# ESP32C3 register map
File version: 1.0
CPU: RISC-V RV32IMC single-core 1, little endian, no MPU, FPU, 3 interrupt priority bits
Registers are 32-bit, read-write, reset 0x0 unless marked. A register's access mark holds for its fields unless they carry their own. Offsets are from the block's base; [hi:lo] are bit positions; {n}, {i} and the like mark numbered series.

## SENSITIVE
Base 0x600C1000
0x00 SENSITIVE_ROM_TABLE_LOCK
  [0] SENSITIVE_ROM_TABLE_LOCK
0x04 SENSITIVE_ROM_TABLE
0x08 SENSITIVE_PRIVILEGE_MODE_SEL_LOCK
  [0] SENSITIVE_PRIVILEGE_MODE_SEL_LOCK
0x0C SENSITIVE_PRIVILEGE_MODE_SEL
  [0] SENSITIVE_PRIVILEGE_MODE_SEL
0x10 SENSITIVE_APB_PERIPHERAL_ACCESS_0
  [0] SENSITIVE_APB_PERIPHERAL_ACCESS_LOCK
0x14 SENSITIVE_APB_PERIPHERAL_ACCESS_1
  [0] SENSITIVE_APB_PERIPHERAL_ACCESS_SPLIT_BURST
0x18 SENSITIVE_INTERNAL_SRAM_USAGE_0
  [0] SENSITIVE_INTERNAL_SRAM_USAGE_LOCK
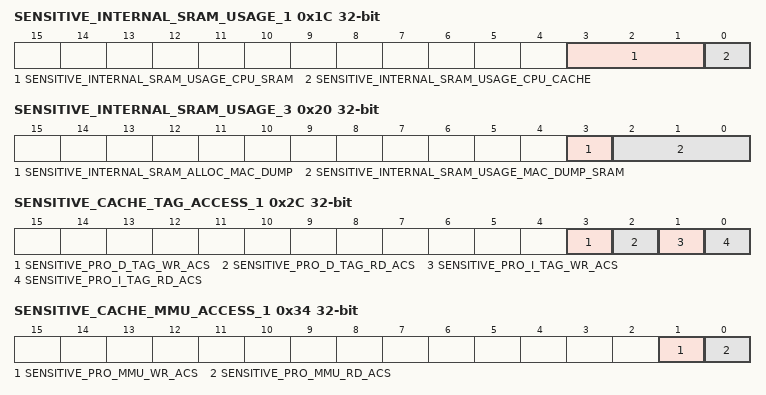
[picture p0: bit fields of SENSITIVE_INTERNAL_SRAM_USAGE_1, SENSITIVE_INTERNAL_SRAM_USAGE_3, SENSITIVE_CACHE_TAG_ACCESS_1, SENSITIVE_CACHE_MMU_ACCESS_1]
0x1C SENSITIVE_INTERNAL_SRAM_USAGE_1
  [3:1] SENSITIVE_INTERNAL_SRAM_USAGE_CPU_SRAM, [0] SENSITIVE_INTERNAL_SRAM_USAGE_CPU_CACHE
0x20 SENSITIVE_INTERNAL_SRAM_USAGE_3
  [3] SENSITIVE_INTERNAL_SRAM_ALLOC_MAC_DUMP, [2:0] SENSITIVE_INTERNAL_SRAM_USAGE_MAC_DUMP_SRAM
0x24 SENSITIVE_INTERNAL_SRAM_USAGE_4
  [0] SENSITIVE_INTERNAL_SRAM_USAGE_LOG_SRAM
0x28 SENSITIVE_CACHE_TAG_ACCESS_0
  [0] SENSITIVE_CACHE_TAG_ACCESS_LOCK
0x2C SENSITIVE_CACHE_TAG_ACCESS_1
  [3] SENSITIVE_PRO_D_TAG_WR_ACS, [2] SENSITIVE_PRO_D_TAG_RD_ACS, [1] SENSITIVE_PRO_I_TAG_WR_ACS, [0] SENSITIVE_PRO_I_TAG_RD_ACS
0x30 SENSITIVE_CACHE_MMU_ACCESS_0
  [0] SENSITIVE_CACHE_MMU_ACCESS_LOCK
0x34 SENSITIVE_CACHE_MMU_ACCESS_1
  [1] SENSITIVE_PRO_MMU_WR_ACS, [0] SENSITIVE_PRO_MMU_RD_ACS
0x38 SENSITIVE_DMA_APBPERI_SPI2_PMS_CONSTRAIN_0
  [0] SENSITIVE_DMA_APBPERI_SPI2_PMS_CONSTRAIN_LOCK
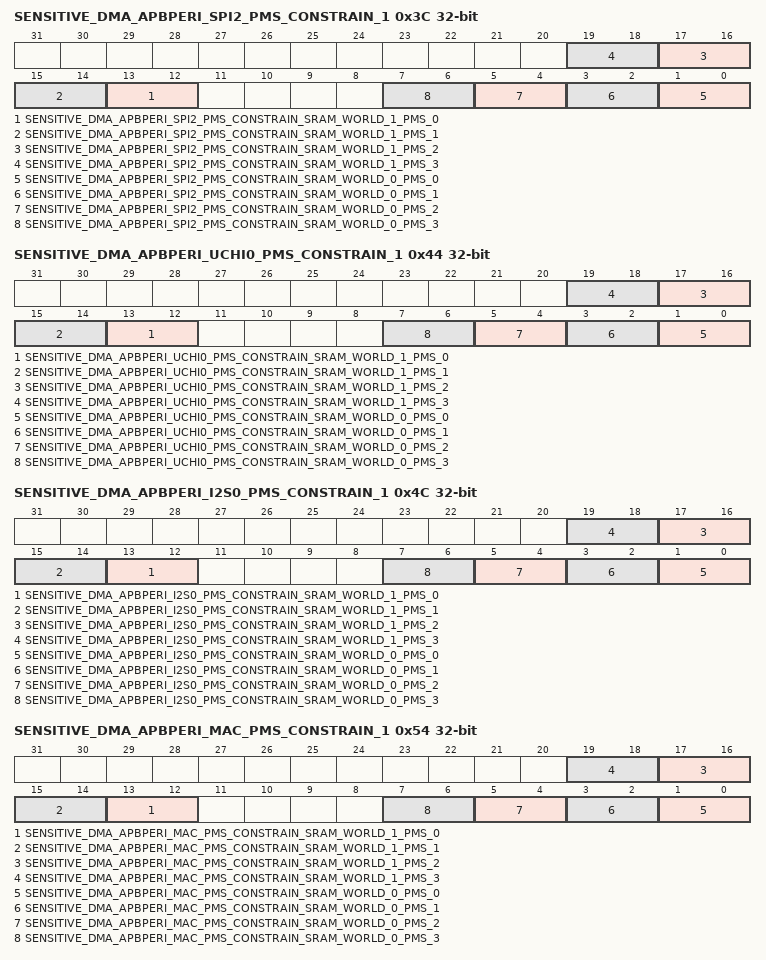
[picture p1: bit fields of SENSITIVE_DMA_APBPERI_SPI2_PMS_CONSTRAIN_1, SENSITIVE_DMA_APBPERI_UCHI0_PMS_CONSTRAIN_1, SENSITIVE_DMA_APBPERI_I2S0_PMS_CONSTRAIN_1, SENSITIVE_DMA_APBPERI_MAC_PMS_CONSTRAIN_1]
0x3C SENSITIVE_DMA_APBPERI_SPI2_PMS_CONSTRAIN_1
  [2n+13:2n+12] SENSITIVE_DMA_APBPERI_SPI2_PMS_CONSTRAIN_SRAM_WORLD_1_PMS_{n} (n=0..3), [2n+1:2n] SENSITIVE_DMA_APBPERI_SPI2_PMS_CONSTRAIN_SRAM_WORLD_0_PMS_{n} (n=0..3)
0x40 SENSITIVE_DMA_APBPERI_UCHI0_PMS_CONSTRAIN_0
  [0] SENSITIVE_DMA_APBPERI_UCHI0_PMS_CONSTRAIN_LOCK
0x44 SENSITIVE_DMA_APBPERI_UCHI0_PMS_CONSTRAIN_1
  [2n+13:2n+12] SENSITIVE_DMA_APBPERI_UCHI0_PMS_CONSTRAIN_SRAM_WORLD_1_PMS_{n} (n=0..3), [2n+1:2n] SENSITIVE_DMA_APBPERI_UCHI0_PMS_CONSTRAIN_SRAM_WORLD_0_PMS_{n} (n=0..3)
0x48 SENSITIVE_DMA_APBPERI_I2S0_PMS_CONSTRAIN_0
  [0] SENSITIVE_DMA_APBPERI_I2S0_PMS_CONSTRAIN_LOCK
0x4C SENSITIVE_DMA_APBPERI_I2S0_PMS_CONSTRAIN_1
  [2n+13:2n+12] SENSITIVE_DMA_APBPERI_I2S0_PMS_CONSTRAIN_SRAM_WORLD_1_PMS_{n} (n=0..3), [2n+1:2n] SENSITIVE_DMA_APBPERI_I2S0_PMS_CONSTRAIN_SRAM_WORLD_0_PMS_{n} (n=0..3)
0x50 SENSITIVE_DMA_APBPERI_MAC_PMS_CONSTRAIN_0
  [0] SENSITIVE_DMA_APBPERI_MAC_PMS_CONSTRAIN_LOCK
0x54 SENSITIVE_DMA_APBPERI_MAC_PMS_CONSTRAIN_1
  [2n+13:2n+12] SENSITIVE_DMA_APBPERI_MAC_PMS_CONSTRAIN_SRAM_WORLD_1_PMS_{n} (n=0..3), [2n+1:2n] SENSITIVE_DMA_APBPERI_MAC_PMS_CONSTRAIN_SRAM_WORLD_0_PMS_{n} (n=0..3)
0x58 SENSITIVE_DMA_APBPERI_BACKUP_PMS_CONSTRAIN_0
  [0] SENSITIVE_DMA_APBPERI_BACKUP_PMS_CONSTRAIN_LOCK
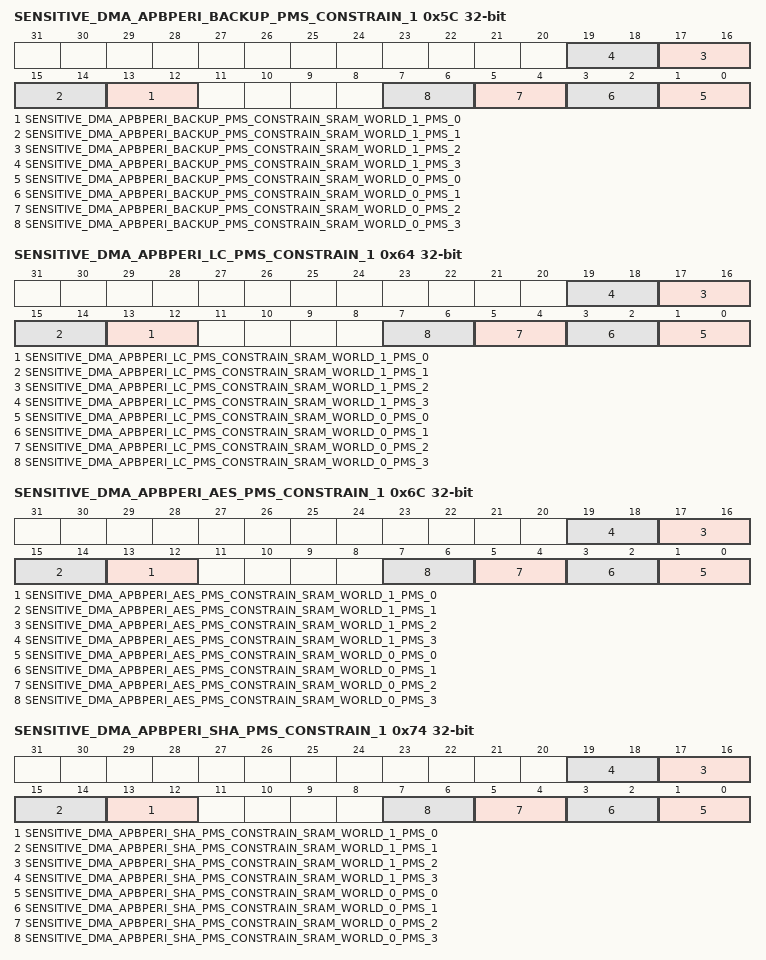
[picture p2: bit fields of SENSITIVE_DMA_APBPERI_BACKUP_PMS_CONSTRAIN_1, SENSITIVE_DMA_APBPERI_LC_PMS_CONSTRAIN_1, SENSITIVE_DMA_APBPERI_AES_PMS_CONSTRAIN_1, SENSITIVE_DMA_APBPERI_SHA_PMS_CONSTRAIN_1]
0x5C SENSITIVE_DMA_APBPERI_BACKUP_PMS_CONSTRAIN_1
  [2n+13:2n+12] SENSITIVE_DMA_APBPERI_BACKUP_PMS_CONSTRAIN_SRAM_WORLD_1_PMS_{n} (n=0..3), [2n+1:2n] SENSITIVE_DMA_APBPERI_BACKUP_PMS_CONSTRAIN_SRAM_WORLD_0_PMS_{n} (n=0..3)
0x60 SENSITIVE_DMA_APBPERI_LC_PMS_CONSTRAIN_0
  [0] SENSITIVE_DMA_APBPERI_LC_PMS_CONSTRAIN_LOCK
0x64 SENSITIVE_DMA_APBPERI_LC_PMS_CONSTRAIN_1
  [2n+13:2n+12] SENSITIVE_DMA_APBPERI_LC_PMS_CONSTRAIN_SRAM_WORLD_1_PMS_{n} (n=0..3), [2n+1:2n] SENSITIVE_DMA_APBPERI_LC_PMS_CONSTRAIN_SRAM_WORLD_0_PMS_{n} (n=0..3)
0x68 SENSITIVE_DMA_APBPERI_AES_PMS_CONSTRAIN_0
  [0] SENSITIVE_DMA_APBPERI_AES_PMS_CONSTRAIN_LOCK
0x6C SENSITIVE_DMA_APBPERI_AES_PMS_CONSTRAIN_1
  [2n+13:2n+12] SENSITIVE_DMA_APBPERI_AES_PMS_CONSTRAIN_SRAM_WORLD_1_PMS_{n} (n=0..3), [2n+1:2n] SENSITIVE_DMA_APBPERI_AES_PMS_CONSTRAIN_SRAM_WORLD_0_PMS_{n} (n=0..3)
0x70 SENSITIVE_DMA_APBPERI_SHA_PMS_CONSTRAIN_0
  [0] SENSITIVE_DMA_APBPERI_SHA_PMS_CONSTRAIN_LOCK
0x74 SENSITIVE_DMA_APBPERI_SHA_PMS_CONSTRAIN_1
  [2n+13:2n+12] SENSITIVE_DMA_APBPERI_SHA_PMS_CONSTRAIN_SRAM_WORLD_1_PMS_{n} (n=0..3), [2n+1:2n] SENSITIVE_DMA_APBPERI_SHA_PMS_CONSTRAIN_SRAM_WORLD_0_PMS_{n} (n=0..3)
0x78 SENSITIVE_DMA_APBPERI_ADC_DAC_PMS_CONSTRAIN_0
  [0] SENSITIVE_DMA_APBPERI_ADC_DAC_PMS_CONSTRAIN_LOCK
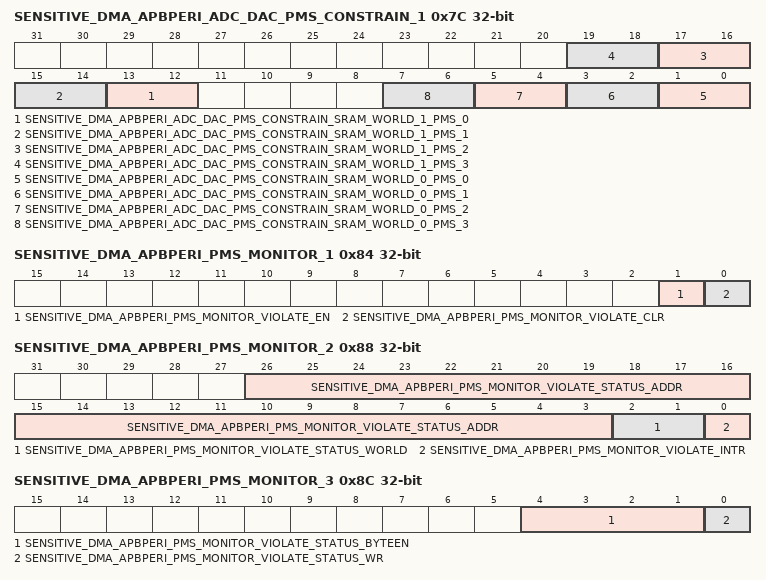
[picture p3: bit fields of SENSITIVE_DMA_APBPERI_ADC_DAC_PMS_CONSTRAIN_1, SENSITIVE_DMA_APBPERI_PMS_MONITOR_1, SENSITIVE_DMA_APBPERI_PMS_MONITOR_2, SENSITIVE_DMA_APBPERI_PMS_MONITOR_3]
0x7C SENSITIVE_DMA_APBPERI_ADC_DAC_PMS_CONSTRAIN_1
  [2n+13:2n+12] SENSITIVE_DMA_APBPERI_ADC_DAC_PMS_CONSTRAIN_SRAM_WORLD_1_PMS_{n} (n=0..3), [2n+1:2n] SENSITIVE_DMA_APBPERI_ADC_DAC_PMS_CONSTRAIN_SRAM_WORLD_0_PMS_{n} (n=0..3)
0x80 SENSITIVE_DMA_APBPERI_PMS_MONITOR_0
  [0] SENSITIVE_DMA_APBPERI_PMS_MONITOR_LOCK
0x84 SENSITIVE_DMA_APBPERI_PMS_MONITOR_1
  [1] SENSITIVE_DMA_APBPERI_PMS_MONITOR_VIOLATE_EN, [0] SENSITIVE_DMA_APBPERI_PMS_MONITOR_VIOLATE_CLR
0x88 SENSITIVE_DMA_APBPERI_PMS_MONITOR_2 ro
  [26:3] SENSITIVE_DMA_APBPERI_PMS_MONITOR_VIOLATE_STATUS_ADDR, [2:1] SENSITIVE_DMA_APBPERI_PMS_MONITOR_VIOLATE_STATUS_WORLD, [0] SENSITIVE_DMA_APBPERI_PMS_MONITOR_VIOLATE_INTR
0x8C SENSITIVE_DMA_APBPERI_PMS_MONITOR_3 ro
  [4:1] SENSITIVE_DMA_APBPERI_PMS_MONITOR_VIOLATE_STATUS_BYTEEN, [0] SENSITIVE_DMA_APBPERI_PMS_MONITOR_VIOLATE_STATUS_WR
0x90 SENSITIVE_CORE_X_IRAM0_DRAM0_DMA_SPLIT_LINE_CONSTRAIN_0
  [0] SENSITIVE_CORE_X_IRAM0_DRAM0_DMA_SPLIT_LINE_CONSTRAIN_LOCK
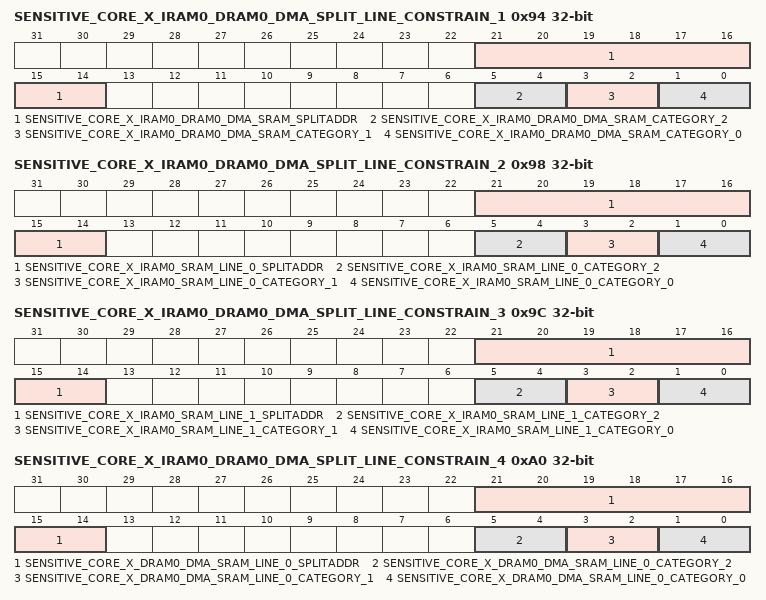
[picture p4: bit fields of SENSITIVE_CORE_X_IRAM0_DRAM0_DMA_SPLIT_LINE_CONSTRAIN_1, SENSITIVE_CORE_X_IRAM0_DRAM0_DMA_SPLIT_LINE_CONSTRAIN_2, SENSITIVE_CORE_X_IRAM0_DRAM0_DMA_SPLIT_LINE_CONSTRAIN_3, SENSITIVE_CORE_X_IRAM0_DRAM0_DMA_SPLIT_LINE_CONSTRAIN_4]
0x94 SENSITIVE_CORE_X_IRAM0_DRAM0_DMA_SPLIT_LINE_CONSTRAIN_1
  [21:14] SENSITIVE_CORE_X_IRAM0_DRAM0_DMA_SRAM_SPLITADDR, [5:4] SENSITIVE_CORE_X_IRAM0_DRAM0_DMA_SRAM_CATEGORY_2, [3:2] SENSITIVE_CORE_X_IRAM0_DRAM0_DMA_SRAM_CATEGORY_1, [1:0] SENSITIVE_CORE_X_IRAM0_DRAM0_DMA_SRAM_CATEGORY_0
0x98 SENSITIVE_CORE_X_IRAM0_DRAM0_DMA_SPLIT_LINE_CONSTRAIN_2
  [21:14] SENSITIVE_CORE_X_IRAM0_SRAM_LINE_0_SPLITADDR, [5:4] SENSITIVE_CORE_X_IRAM0_SRAM_LINE_0_CATEGORY_2, [3:2] SENSITIVE_CORE_X_IRAM0_SRAM_LINE_0_CATEGORY_1, [1:0] SENSITIVE_CORE_X_IRAM0_SRAM_LINE_0_CATEGORY_0
0x9C SENSITIVE_CORE_X_IRAM0_DRAM0_DMA_SPLIT_LINE_CONSTRAIN_3
  [21:14] SENSITIVE_CORE_X_IRAM0_SRAM_LINE_1_SPLITADDR, [5:4] SENSITIVE_CORE_X_IRAM0_SRAM_LINE_1_CATEGORY_2, [3:2] SENSITIVE_CORE_X_IRAM0_SRAM_LINE_1_CATEGORY_1, [1:0] SENSITIVE_CORE_X_IRAM0_SRAM_LINE_1_CATEGORY_0
0xA0 SENSITIVE_CORE_X_IRAM0_DRAM0_DMA_SPLIT_LINE_CONSTRAIN_4
  [21:14] SENSITIVE_CORE_X_DRAM0_DMA_SRAM_LINE_0_SPLITADDR, [5:4] SENSITIVE_CORE_X_DRAM0_DMA_SRAM_LINE_0_CATEGORY_2, [3:2] SENSITIVE_CORE_X_DRAM0_DMA_SRAM_LINE_0_CATEGORY_1, [1:0] SENSITIVE_CORE_X_DRAM0_DMA_SRAM_LINE_0_CATEGORY_0
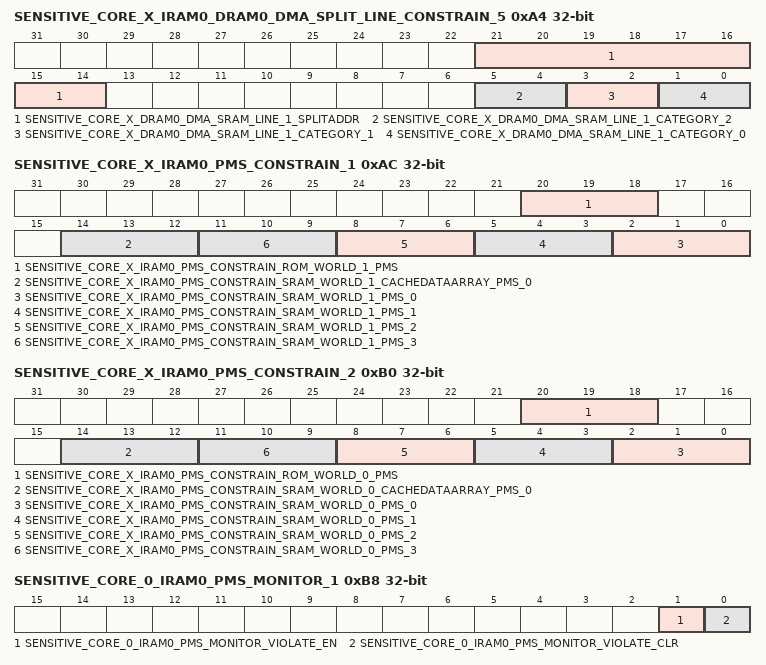
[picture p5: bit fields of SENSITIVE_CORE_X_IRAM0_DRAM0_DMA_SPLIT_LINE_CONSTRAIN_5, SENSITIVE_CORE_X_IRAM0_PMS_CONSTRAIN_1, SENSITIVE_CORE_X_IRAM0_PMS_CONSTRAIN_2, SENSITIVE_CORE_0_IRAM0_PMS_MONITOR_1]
0xA4 SENSITIVE_CORE_X_IRAM0_DRAM0_DMA_SPLIT_LINE_CONSTRAIN_5
  [21:14] SENSITIVE_CORE_X_DRAM0_DMA_SRAM_LINE_1_SPLITADDR, [5:4] SENSITIVE_CORE_X_DRAM0_DMA_SRAM_LINE_1_CATEGORY_2, [3:2] SENSITIVE_CORE_X_DRAM0_DMA_SRAM_LINE_1_CATEGORY_1, [1:0] SENSITIVE_CORE_X_DRAM0_DMA_SRAM_LINE_1_CATEGORY_0
0xA8 SENSITIVE_CORE_X_IRAM0_PMS_CONSTRAIN_0
  [0] SENSITIVE_CORE_X_IRAM0_PMS_CONSTRAIN_LOCK
0xAC SENSITIVE_CORE_X_IRAM0_PMS_CONSTRAIN_1
  [20:18] SENSITIVE_CORE_X_IRAM0_PMS_CONSTRAIN_ROM_WORLD_1_PMS, [14:12] SENSITIVE_CORE_X_IRAM0_PMS_CONSTRAIN_SRAM_WORLD_1_CACHEDATAARRAY_PMS_0, [3n+2:3n] SENSITIVE_CORE_X_IRAM0_PMS_CONSTRAIN_SRAM_WORLD_1_PMS_{n} (n=0..3)
0xB0 SENSITIVE_CORE_X_IRAM0_PMS_CONSTRAIN_2
  [20:18] SENSITIVE_CORE_X_IRAM0_PMS_CONSTRAIN_ROM_WORLD_0_PMS, [14:12] SENSITIVE_CORE_X_IRAM0_PMS_CONSTRAIN_SRAM_WORLD_0_CACHEDATAARRAY_PMS_0, [3n+2:3n] SENSITIVE_CORE_X_IRAM0_PMS_CONSTRAIN_SRAM_WORLD_0_PMS_{n} (n=0..3)
0xB4 SENSITIVE_CORE_0_IRAM0_PMS_MONITOR_0
  [0] SENSITIVE_CORE_0_IRAM0_PMS_MONITOR_LOCK
0xB8 SENSITIVE_CORE_0_IRAM0_PMS_MONITOR_1
  [1] SENSITIVE_CORE_0_IRAM0_PMS_MONITOR_VIOLATE_EN, [0] SENSITIVE_CORE_0_IRAM0_PMS_MONITOR_VIOLATE_CLR
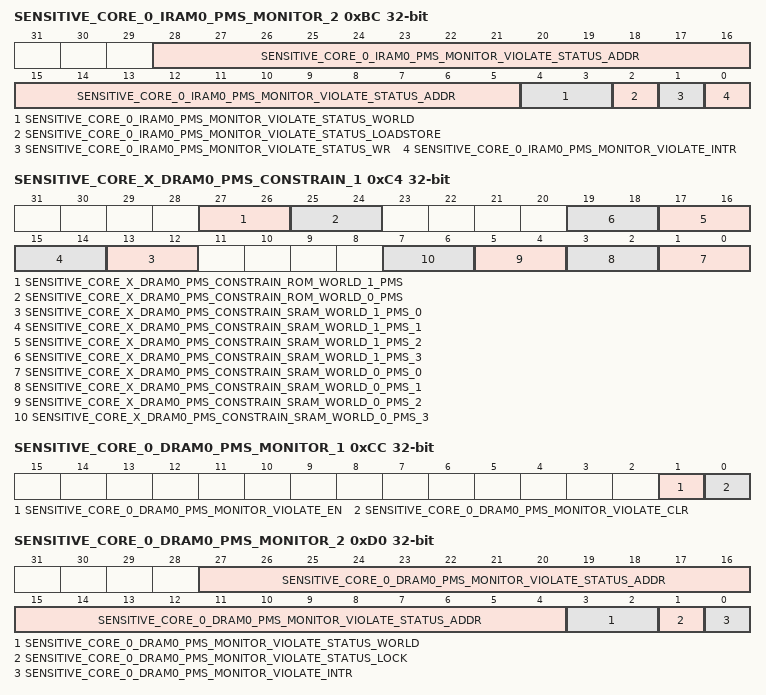
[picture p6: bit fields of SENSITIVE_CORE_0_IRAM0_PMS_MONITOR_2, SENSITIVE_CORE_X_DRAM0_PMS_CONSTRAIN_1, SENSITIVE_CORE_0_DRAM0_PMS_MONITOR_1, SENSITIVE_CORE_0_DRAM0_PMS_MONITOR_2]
0xBC SENSITIVE_CORE_0_IRAM0_PMS_MONITOR_2 ro
  [28:5] SENSITIVE_CORE_0_IRAM0_PMS_MONITOR_VIOLATE_STATUS_ADDR, [4:3] SENSITIVE_CORE_0_IRAM0_PMS_MONITOR_VIOLATE_STATUS_WORLD, [2] SENSITIVE_CORE_0_IRAM0_PMS_MONITOR_VIOLATE_STATUS_LOADSTORE, [1] SENSITIVE_CORE_0_IRAM0_PMS_MONITOR_VIOLATE_STATUS_WR, [0] SENSITIVE_CORE_0_IRAM0_PMS_MONITOR_VIOLATE_INTR
0xC0 SENSITIVE_CORE_X_DRAM0_PMS_CONSTRAIN_0
  [0] SENSITIVE_CORE_X_DRAM0_PMS_CONSTRAIN_LOCK
0xC4 SENSITIVE_CORE_X_DRAM0_PMS_CONSTRAIN_1
  [27:26] SENSITIVE_CORE_X_DRAM0_PMS_CONSTRAIN_ROM_WORLD_1_PMS, [25:24] SENSITIVE_CORE_X_DRAM0_PMS_CONSTRAIN_ROM_WORLD_0_PMS, [2n+13:2n+12] SENSITIVE_CORE_X_DRAM0_PMS_CONSTRAIN_SRAM_WORLD_1_PMS_{n} (n=0..3), [2n+1:2n] SENSITIVE_CORE_X_DRAM0_PMS_CONSTRAIN_SRAM_WORLD_0_PMS_{n} (n=0..3)
0xC8 SENSITIVE_CORE_0_DRAM0_PMS_MONITOR_0
  [0] SENSITIVE_CORE_0_DRAM0_PMS_MONITOR_LOCK
0xCC SENSITIVE_CORE_0_DRAM0_PMS_MONITOR_1
  [1] SENSITIVE_CORE_0_DRAM0_PMS_MONITOR_VIOLATE_EN, [0] SENSITIVE_CORE_0_DRAM0_PMS_MONITOR_VIOLATE_CLR
0xD0 SENSITIVE_CORE_0_DRAM0_PMS_MONITOR_2 ro
  [27:4] SENSITIVE_CORE_0_DRAM0_PMS_MONITOR_VIOLATE_STATUS_ADDR, [3:2] SENSITIVE_CORE_0_DRAM0_PMS_MONITOR_VIOLATE_STATUS_WORLD, [1] SENSITIVE_CORE_0_DRAM0_PMS_MONITOR_VIOLATE_STATUS_LOCK, [0] SENSITIVE_CORE_0_DRAM0_PMS_MONITOR_VIOLATE_INTR
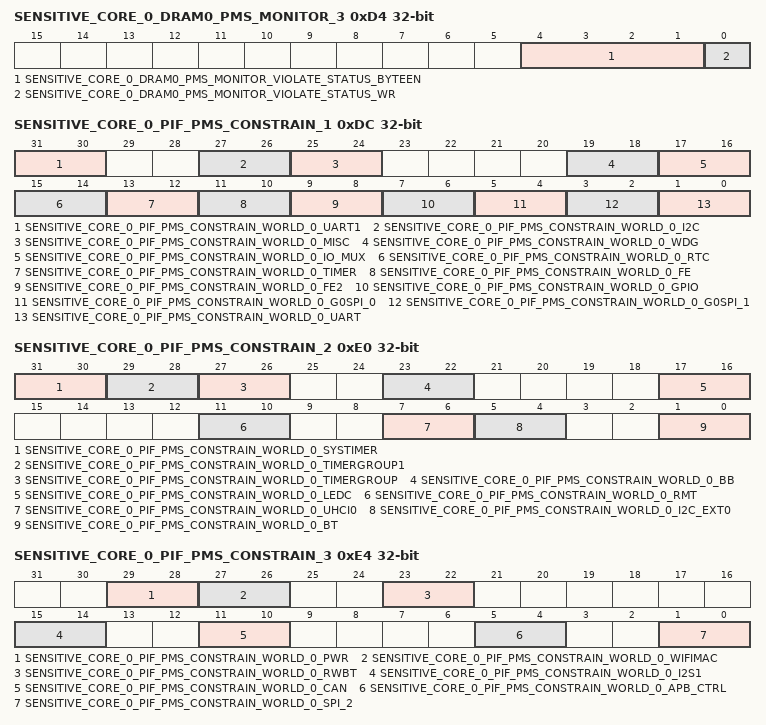
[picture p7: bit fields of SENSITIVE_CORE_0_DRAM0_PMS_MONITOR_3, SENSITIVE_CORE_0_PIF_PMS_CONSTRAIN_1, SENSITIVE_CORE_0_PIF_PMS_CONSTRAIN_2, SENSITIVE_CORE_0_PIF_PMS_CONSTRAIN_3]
0xD4 SENSITIVE_CORE_0_DRAM0_PMS_MONITOR_3 ro
  [4:1] SENSITIVE_CORE_0_DRAM0_PMS_MONITOR_VIOLATE_STATUS_BYTEEN, [0] SENSITIVE_CORE_0_DRAM0_PMS_MONITOR_VIOLATE_STATUS_WR
0xD8 SENSITIVE_CORE_0_PIF_PMS_CONSTRAIN_0
  [0] SENSITIVE_CORE_0_PIF_PMS_CONSTRAIN_LOCK
0xDC SENSITIVE_CORE_0_PIF_PMS_CONSTRAIN_1
  [31:30] SENSITIVE_CORE_0_PIF_PMS_CONSTRAIN_WORLD_0_UART1, [27:26] SENSITIVE_CORE_0_PIF_PMS_CONSTRAIN_WORLD_0_I2C, [25:24] SENSITIVE_CORE_0_PIF_PMS_CONSTRAIN_WORLD_0_MISC, [19:18] SENSITIVE_CORE_0_PIF_PMS_CONSTRAIN_WORLD_0_WDG, [17:16] SENSITIVE_CORE_0_PIF_PMS_CONSTRAIN_WORLD_0_IO_MUX, [15:14] SENSITIVE_CORE_0_PIF_PMS_CONSTRAIN_WORLD_0_RTC, [13:12] SENSITIVE_CORE_0_PIF_PMS_CONSTRAIN_WORLD_0_TIMER, [11:10] SENSITIVE_CORE_0_PIF_PMS_CONSTRAIN_WORLD_0_FE, [9:8] SENSITIVE_CORE_0_PIF_PMS_CONSTRAIN_WORLD_0_FE2, [7:6] SENSITIVE_CORE_0_PIF_PMS_CONSTRAIN_WORLD_0_GPIO, [5:4] SENSITIVE_CORE_0_PIF_PMS_CONSTRAIN_WORLD_0_G0SPI_0, [3:2] SENSITIVE_CORE_0_PIF_PMS_CONSTRAIN_WORLD_0_G0SPI_1, [1:0] SENSITIVE_CORE_0_PIF_PMS_CONSTRAIN_WORLD_0_UART
0xE0 SENSITIVE_CORE_0_PIF_PMS_CONSTRAIN_2
  [31:30] SENSITIVE_CORE_0_PIF_PMS_CONSTRAIN_WORLD_0_SYSTIMER, [29:28] SENSITIVE_CORE_0_PIF_PMS_CONSTRAIN_WORLD_0_TIMERGROUP1, [27:26] SENSITIVE_CORE_0_PIF_PMS_CONSTRAIN_WORLD_0_TIMERGROUP, [23:22] SENSITIVE_CORE_0_PIF_PMS_CONSTRAIN_WORLD_0_BB, [17:16] SENSITIVE_CORE_0_PIF_PMS_CONSTRAIN_WORLD_0_LEDC, [11:10] SENSITIVE_CORE_0_PIF_PMS_CONSTRAIN_WORLD_0_RMT, [7:6] SENSITIVE_CORE_0_PIF_PMS_CONSTRAIN_WORLD_0_UHCI0, [5:4] SENSITIVE_CORE_0_PIF_PMS_CONSTRAIN_WORLD_0_I2C_EXT0, [1:0] SENSITIVE_CORE_0_PIF_PMS_CONSTRAIN_WORLD_0_BT
0xE4 SENSITIVE_CORE_0_PIF_PMS_CONSTRAIN_3
  [29:28] SENSITIVE_CORE_0_PIF_PMS_CONSTRAIN_WORLD_0_PWR, [27:26] SENSITIVE_CORE_0_PIF_PMS_CONSTRAIN_WORLD_0_WIFIMAC, [23:22] SENSITIVE_CORE_0_PIF_PMS_CONSTRAIN_WORLD_0_RWBT, [15:14] SENSITIVE_CORE_0_PIF_PMS_CONSTRAIN_WORLD_0_I2S1, [11:10] SENSITIVE_CORE_0_PIF_PMS_CONSTRAIN_WORLD_0_CAN, [5:4] SENSITIVE_CORE_0_PIF_PMS_CONSTRAIN_WORLD_0_APB_CTRL, [1:0] SENSITIVE_CORE_0_PIF_PMS_CONSTRAIN_WORLD_0_SPI_2
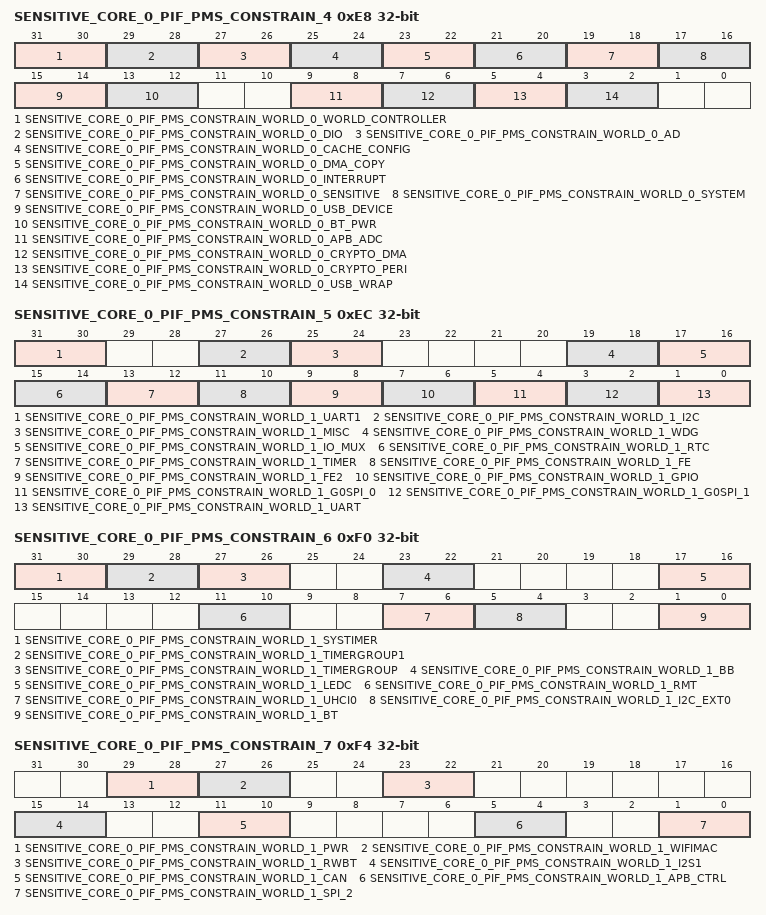
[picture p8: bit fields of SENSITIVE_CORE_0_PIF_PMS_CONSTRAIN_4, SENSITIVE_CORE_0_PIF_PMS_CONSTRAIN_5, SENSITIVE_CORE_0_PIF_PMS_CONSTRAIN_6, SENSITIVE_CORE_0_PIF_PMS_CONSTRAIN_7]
0xE8 SENSITIVE_CORE_0_PIF_PMS_CONSTRAIN_4
  [31:30] SENSITIVE_CORE_0_PIF_PMS_CONSTRAIN_WORLD_0_WORLD_CONTROLLER, [29:28] SENSITIVE_CORE_0_PIF_PMS_CONSTRAIN_WORLD_0_DIO, [27:26] SENSITIVE_CORE_0_PIF_PMS_CONSTRAIN_WORLD_0_AD, [25:24] SENSITIVE_CORE_0_PIF_PMS_CONSTRAIN_WORLD_0_CACHE_CONFIG, [23:22] SENSITIVE_CORE_0_PIF_PMS_CONSTRAIN_WORLD_0_DMA_COPY, [21:20] SENSITIVE_CORE_0_PIF_PMS_CONSTRAIN_WORLD_0_INTERRUPT, [19:18] SENSITIVE_CORE_0_PIF_PMS_CONSTRAIN_WORLD_0_SENSITIVE, [17:16] SENSITIVE_CORE_0_PIF_PMS_CONSTRAIN_WORLD_0_SYSTEM, [15:14] SENSITIVE_CORE_0_PIF_PMS_CONSTRAIN_WORLD_0_USB_DEVICE, [13:12] SENSITIVE_CORE_0_PIF_PMS_CONSTRAIN_WORLD_0_BT_PWR, [9:8] SENSITIVE_CORE_0_PIF_PMS_CONSTRAIN_WORLD_0_APB_ADC, [7:6] SENSITIVE_CORE_0_PIF_PMS_CONSTRAIN_WORLD_0_CRYPTO_DMA, [5:4] SENSITIVE_CORE_0_PIF_PMS_CONSTRAIN_WORLD_0_CRYPTO_PERI, [3:2] SENSITIVE_CORE_0_PIF_PMS_CONSTRAIN_WORLD_0_USB_WRAP
0xEC SENSITIVE_CORE_0_PIF_PMS_CONSTRAIN_5
  [31:30] SENSITIVE_CORE_0_PIF_PMS_CONSTRAIN_WORLD_1_UART1, [27:26] SENSITIVE_CORE_0_PIF_PMS_CONSTRAIN_WORLD_1_I2C, [25:24] SENSITIVE_CORE_0_PIF_PMS_CONSTRAIN_WORLD_1_MISC, [19:18] SENSITIVE_CORE_0_PIF_PMS_CONSTRAIN_WORLD_1_WDG, [17:16] SENSITIVE_CORE_0_PIF_PMS_CONSTRAIN_WORLD_1_IO_MUX, [15:14] SENSITIVE_CORE_0_PIF_PMS_CONSTRAIN_WORLD_1_RTC, [13:12] SENSITIVE_CORE_0_PIF_PMS_CONSTRAIN_WORLD_1_TIMER, [11:10] SENSITIVE_CORE_0_PIF_PMS_CONSTRAIN_WORLD_1_FE, [9:8] SENSITIVE_CORE_0_PIF_PMS_CONSTRAIN_WORLD_1_FE2, [7:6] SENSITIVE_CORE_0_PIF_PMS_CONSTRAIN_WORLD_1_GPIO, [5:4] SENSITIVE_CORE_0_PIF_PMS_CONSTRAIN_WORLD_1_G0SPI_0, [3:2] SENSITIVE_CORE_0_PIF_PMS_CONSTRAIN_WORLD_1_G0SPI_1, [1:0] SENSITIVE_CORE_0_PIF_PMS_CONSTRAIN_WORLD_1_UART
0xF0 SENSITIVE_CORE_0_PIF_PMS_CONSTRAIN_6
  [31:30] SENSITIVE_CORE_0_PIF_PMS_CONSTRAIN_WORLD_1_SYSTIMER, [29:28] SENSITIVE_CORE_0_PIF_PMS_CONSTRAIN_WORLD_1_TIMERGROUP1, [27:26] SENSITIVE_CORE_0_PIF_PMS_CONSTRAIN_WORLD_1_TIMERGROUP, [23:22] SENSITIVE_CORE_0_PIF_PMS_CONSTRAIN_WORLD_1_BB, [17:16] SENSITIVE_CORE_0_PIF_PMS_CONSTRAIN_WORLD_1_LEDC, [11:10] SENSITIVE_CORE_0_PIF_PMS_CONSTRAIN_WORLD_1_RMT, [7:6] SENSITIVE_CORE_0_PIF_PMS_CONSTRAIN_WORLD_1_UHCI0, [5:4] SENSITIVE_CORE_0_PIF_PMS_CONSTRAIN_WORLD_1_I2C_EXT0, [1:0] SENSITIVE_CORE_0_PIF_PMS_CONSTRAIN_WORLD_1_BT
0xF4 SENSITIVE_CORE_0_PIF_PMS_CONSTRAIN_7
  [29:28] SENSITIVE_CORE_0_PIF_PMS_CONSTRAIN_WORLD_1_PWR, [27:26] SENSITIVE_CORE_0_PIF_PMS_CONSTRAIN_WORLD_1_WIFIMAC, [23:22] SENSITIVE_CORE_0_PIF_PMS_CONSTRAIN_WORLD_1_RWBT, [15:14] SENSITIVE_CORE_0_PIF_PMS_CONSTRAIN_WORLD_1_I2S1, [11:10] SENSITIVE_CORE_0_PIF_PMS_CONSTRAIN_WORLD_1_CAN, [5:4] SENSITIVE_CORE_0_PIF_PMS_CONSTRAIN_WORLD_1_APB_CTRL, [1:0] SENSITIVE_CORE_0_PIF_PMS_CONSTRAIN_WORLD_1_SPI_2
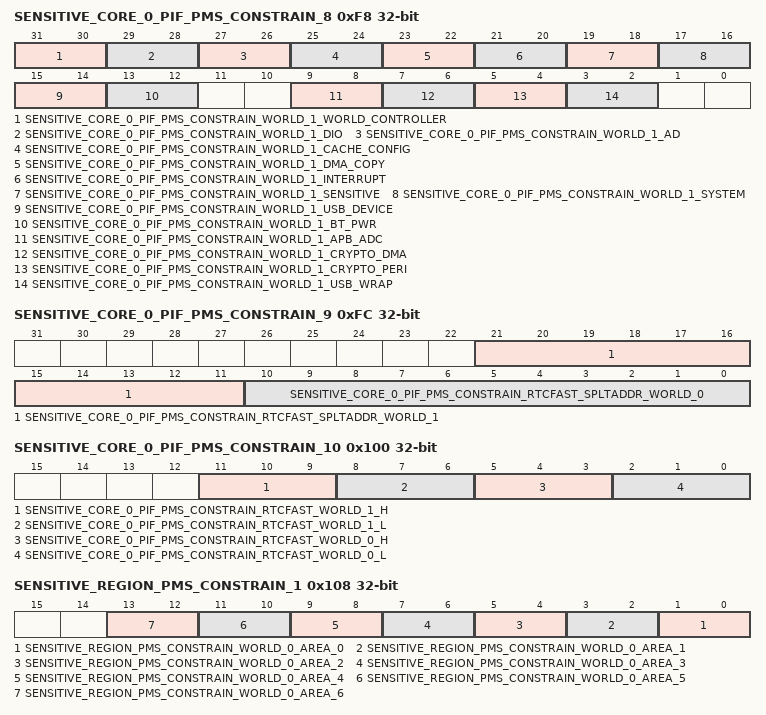
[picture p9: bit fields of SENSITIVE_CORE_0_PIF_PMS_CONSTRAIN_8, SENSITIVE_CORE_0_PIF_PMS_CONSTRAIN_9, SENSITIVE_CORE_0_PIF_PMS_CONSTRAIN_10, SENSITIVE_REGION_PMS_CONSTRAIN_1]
0xF8 SENSITIVE_CORE_0_PIF_PMS_CONSTRAIN_8
  [31:30] SENSITIVE_CORE_0_PIF_PMS_CONSTRAIN_WORLD_1_WORLD_CONTROLLER, [29:28] SENSITIVE_CORE_0_PIF_PMS_CONSTRAIN_WORLD_1_DIO, [27:26] SENSITIVE_CORE_0_PIF_PMS_CONSTRAIN_WORLD_1_AD, [25:24] SENSITIVE_CORE_0_PIF_PMS_CONSTRAIN_WORLD_1_CACHE_CONFIG, [23:22] SENSITIVE_CORE_0_PIF_PMS_CONSTRAIN_WORLD_1_DMA_COPY, [21:20] SENSITIVE_CORE_0_PIF_PMS_CONSTRAIN_WORLD_1_INTERRUPT, [19:18] SENSITIVE_CORE_0_PIF_PMS_CONSTRAIN_WORLD_1_SENSITIVE, [17:16] SENSITIVE_CORE_0_PIF_PMS_CONSTRAIN_WORLD_1_SYSTEM, [15:14] SENSITIVE_CORE_0_PIF_PMS_CONSTRAIN_WORLD_1_USB_DEVICE, [13:12] SENSITIVE_CORE_0_PIF_PMS_CONSTRAIN_WORLD_1_BT_PWR, [9:8] SENSITIVE_CORE_0_PIF_PMS_CONSTRAIN_WORLD_1_APB_ADC, [7:6] SENSITIVE_CORE_0_PIF_PMS_CONSTRAIN_WORLD_1_CRYPTO_DMA, [5:4] SENSITIVE_CORE_0_PIF_PMS_CONSTRAIN_WORLD_1_CRYPTO_PERI, [3:2] SENSITIVE_CORE_0_PIF_PMS_CONSTRAIN_WORLD_1_USB_WRAP
0xFC SENSITIVE_CORE_0_PIF_PMS_CONSTRAIN_9
  [21:11] SENSITIVE_CORE_0_PIF_PMS_CONSTRAIN_RTCFAST_SPLTADDR_WORLD_1, [10:0] SENSITIVE_CORE_0_PIF_PMS_CONSTRAIN_RTCFAST_SPLTADDR_WORLD_0
0x100 SENSITIVE_CORE_0_PIF_PMS_CONSTRAIN_10
  [11:9] SENSITIVE_CORE_0_PIF_PMS_CONSTRAIN_RTCFAST_WORLD_1_H, [8:6] SENSITIVE_CORE_0_PIF_PMS_CONSTRAIN_RTCFAST_WORLD_1_L, [5:3] SENSITIVE_CORE_0_PIF_PMS_CONSTRAIN_RTCFAST_WORLD_0_H, [2:0] SENSITIVE_CORE_0_PIF_PMS_CONSTRAIN_RTCFAST_WORLD_0_L
0x104 SENSITIVE_REGION_PMS_CONSTRAIN_0
  [0] SENSITIVE_REGION_PMS_CONSTRAIN_LOCK
0x108 SENSITIVE_REGION_PMS_CONSTRAIN_1
  [2n+1:2n] SENSITIVE_REGION_PMS_CONSTRAIN_WORLD_0_AREA_{n} (n=0..6)
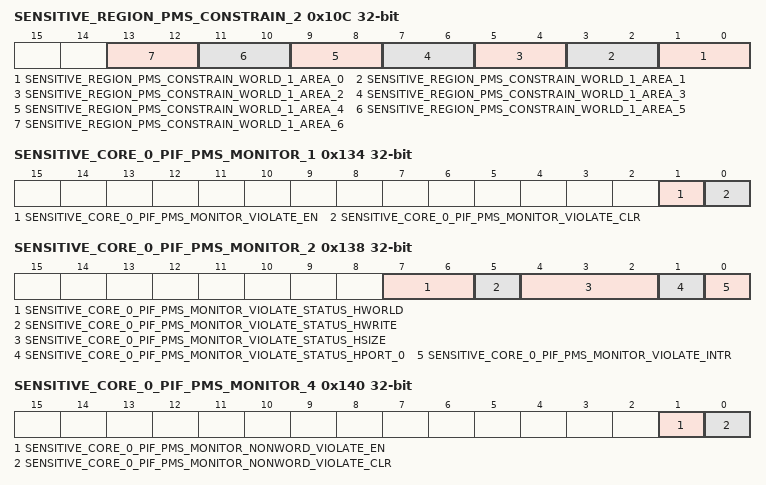
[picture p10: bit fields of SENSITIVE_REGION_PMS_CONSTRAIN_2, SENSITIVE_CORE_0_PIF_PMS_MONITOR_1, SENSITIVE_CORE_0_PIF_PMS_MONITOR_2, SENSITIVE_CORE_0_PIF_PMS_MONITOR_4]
0x10C SENSITIVE_REGION_PMS_CONSTRAIN_2
  [2n+1:2n] SENSITIVE_REGION_PMS_CONSTRAIN_WORLD_1_AREA_{n} (n=0..6)
{0x104+4i} SENSITIVE_REGION_PMS_CONSTRAIN_{i} (i=3..10)
  [29:0] SENSITIVE_REGION_PMS_CONSTRAIN_ADDR_{i-3}
0x130 SENSITIVE_CORE_0_PIF_PMS_MONITOR_0
  [0] SENSITIVE_CORE_0_PIF_PMS_MONITOR_LOCK
0x134 SENSITIVE_CORE_0_PIF_PMS_MONITOR_1
  [1] SENSITIVE_CORE_0_PIF_PMS_MONITOR_VIOLATE_EN, [0] SENSITIVE_CORE_0_PIF_PMS_MONITOR_VIOLATE_CLR
0x138 SENSITIVE_CORE_0_PIF_PMS_MONITOR_2 ro
  [7:6] SENSITIVE_CORE_0_PIF_PMS_MONITOR_VIOLATE_STATUS_HWORLD, [5] SENSITIVE_CORE_0_PIF_PMS_MONITOR_VIOLATE_STATUS_HWRITE, [4:2] SENSITIVE_CORE_0_PIF_PMS_MONITOR_VIOLATE_STATUS_HSIZE, [1] SENSITIVE_CORE_0_PIF_PMS_MONITOR_VIOLATE_STATUS_HPORT_0, [0] SENSITIVE_CORE_0_PIF_PMS_MONITOR_VIOLATE_INTR
0x13C SENSITIVE_CORE_0_PIF_PMS_MONITOR_3 ro
  [31:0] SENSITIVE_CORE_0_PIF_PMS_MONITOR_VIOLATE_STATUS_HADDR
0x140 SENSITIVE_CORE_0_PIF_PMS_MONITOR_4
  [1] SENSITIVE_CORE_0_PIF_PMS_MONITOR_NONWORD_VIOLATE_EN, [0] SENSITIVE_CORE_0_PIF_PMS_MONITOR_NONWORD_VIOLATE_CLR
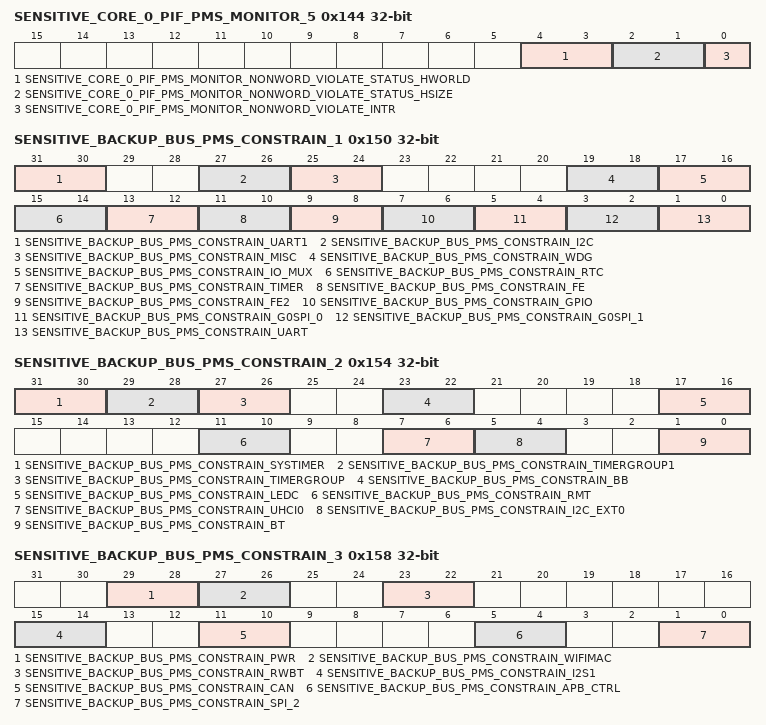
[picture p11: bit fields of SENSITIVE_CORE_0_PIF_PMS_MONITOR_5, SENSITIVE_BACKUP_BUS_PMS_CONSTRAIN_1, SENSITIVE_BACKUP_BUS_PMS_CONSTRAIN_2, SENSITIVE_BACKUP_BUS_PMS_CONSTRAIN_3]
0x144 SENSITIVE_CORE_0_PIF_PMS_MONITOR_5 ro
  [4:3] SENSITIVE_CORE_0_PIF_PMS_MONITOR_NONWORD_VIOLATE_STATUS_HWORLD, [2:1] SENSITIVE_CORE_0_PIF_PMS_MONITOR_NONWORD_VIOLATE_STATUS_HSIZE, [0] SENSITIVE_CORE_0_PIF_PMS_MONITOR_NONWORD_VIOLATE_INTR
0x148 SENSITIVE_CORE_0_PIF_PMS_MONITOR_6 ro
  [31:0] SENSITIVE_CORE_0_PIF_PMS_MONITOR_NONWORD_VIOLATE_STATUS_HADDR
0x14C SENSITIVE_BACKUP_BUS_PMS_CONSTRAIN_0
  [0] SENSITIVE_BACKUP_BUS_PMS_CONSTRAIN_LOCK
0x150 SENSITIVE_BACKUP_BUS_PMS_CONSTRAIN_1
  [31:30] SENSITIVE_BACKUP_BUS_PMS_CONSTRAIN_UART1, [27:26] SENSITIVE_BACKUP_BUS_PMS_CONSTRAIN_I2C, [25:24] SENSITIVE_BACKUP_BUS_PMS_CONSTRAIN_MISC, [19:18] SENSITIVE_BACKUP_BUS_PMS_CONSTRAIN_WDG, [17:16] SENSITIVE_BACKUP_BUS_PMS_CONSTRAIN_IO_MUX, [15:14] SENSITIVE_BACKUP_BUS_PMS_CONSTRAIN_RTC, [13:12] SENSITIVE_BACKUP_BUS_PMS_CONSTRAIN_TIMER, [11:10] SENSITIVE_BACKUP_BUS_PMS_CONSTRAIN_FE, [9:8] SENSITIVE_BACKUP_BUS_PMS_CONSTRAIN_FE2, [7:6] SENSITIVE_BACKUP_BUS_PMS_CONSTRAIN_GPIO, [5:4] SENSITIVE_BACKUP_BUS_PMS_CONSTRAIN_G0SPI_0, [3:2] SENSITIVE_BACKUP_BUS_PMS_CONSTRAIN_G0SPI_1, [1:0] SENSITIVE_BACKUP_BUS_PMS_CONSTRAIN_UART
0x154 SENSITIVE_BACKUP_BUS_PMS_CONSTRAIN_2
  [31:30] SENSITIVE_BACKUP_BUS_PMS_CONSTRAIN_SYSTIMER, [29:28] SENSITIVE_BACKUP_BUS_PMS_CONSTRAIN_TIMERGROUP1, [27:26] SENSITIVE_BACKUP_BUS_PMS_CONSTRAIN_TIMERGROUP, [23:22] SENSITIVE_BACKUP_BUS_PMS_CONSTRAIN_BB, [17:16] SENSITIVE_BACKUP_BUS_PMS_CONSTRAIN_LEDC, [11:10] SENSITIVE_BACKUP_BUS_PMS_CONSTRAIN_RMT, [7:6] SENSITIVE_BACKUP_BUS_PMS_CONSTRAIN_UHCI0, [5:4] SENSITIVE_BACKUP_BUS_PMS_CONSTRAIN_I2C_EXT0, [1:0] SENSITIVE_BACKUP_BUS_PMS_CONSTRAIN_BT
0x158 SENSITIVE_BACKUP_BUS_PMS_CONSTRAIN_3
  [29:28] SENSITIVE_BACKUP_BUS_PMS_CONSTRAIN_PWR, [27:26] SENSITIVE_BACKUP_BUS_PMS_CONSTRAIN_WIFIMAC, [23:22] SENSITIVE_BACKUP_BUS_PMS_CONSTRAIN_RWBT, [15:14] SENSITIVE_BACKUP_BUS_PMS_CONSTRAIN_I2S1, [11:10] SENSITIVE_BACKUP_BUS_PMS_CONSTRAIN_CAN, [5:4] SENSITIVE_BACKUP_BUS_PMS_CONSTRAIN_APB_CTRL, [1:0] SENSITIVE_BACKUP_BUS_PMS_CONSTRAIN_SPI_2
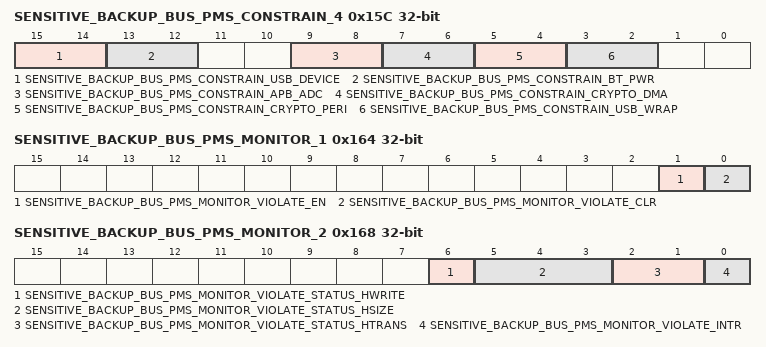
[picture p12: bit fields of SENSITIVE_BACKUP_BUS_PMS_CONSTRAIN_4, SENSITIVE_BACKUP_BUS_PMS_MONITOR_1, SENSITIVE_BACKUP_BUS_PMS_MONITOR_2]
0x15C SENSITIVE_BACKUP_BUS_PMS_CONSTRAIN_4
  [15:14] SENSITIVE_BACKUP_BUS_PMS_CONSTRAIN_USB_DEVICE, [13:12] SENSITIVE_BACKUP_BUS_PMS_CONSTRAIN_BT_PWR, [9:8] SENSITIVE_BACKUP_BUS_PMS_CONSTRAIN_APB_ADC, [7:6] SENSITIVE_BACKUP_BUS_PMS_CONSTRAIN_CRYPTO_DMA, [5:4] SENSITIVE_BACKUP_BUS_PMS_CONSTRAIN_CRYPTO_PERI, [3:2] SENSITIVE_BACKUP_BUS_PMS_CONSTRAIN_USB_WRAP
0x160 SENSITIVE_BACKUP_BUS_PMS_MONITOR_0
  [0] SENSITIVE_BACKUP_BUS_PMS_MONITOR_LOCK
0x164 SENSITIVE_BACKUP_BUS_PMS_MONITOR_1
  [1] SENSITIVE_BACKUP_BUS_PMS_MONITOR_VIOLATE_EN, [0] SENSITIVE_BACKUP_BUS_PMS_MONITOR_VIOLATE_CLR
0x168 SENSITIVE_BACKUP_BUS_PMS_MONITOR_2 ro
  [6] SENSITIVE_BACKUP_BUS_PMS_MONITOR_VIOLATE_STATUS_HWRITE, [5:3] SENSITIVE_BACKUP_BUS_PMS_MONITOR_VIOLATE_STATUS_HSIZE, [2:1] SENSITIVE_BACKUP_BUS_PMS_MONITOR_VIOLATE_STATUS_HTRANS, [0] SENSITIVE_BACKUP_BUS_PMS_MONITOR_VIOLATE_INTR
0x16C SENSITIVE_BACKUP_BUS_PMS_MONITOR_3 ro
  [31:0] SENSITIVE_BACKUP_BUS_PMS_MONITOR_VIOLATE_HADDR
0x170 SENSITIVE_CLOCK_GATE
  [0] SENSITIVE_CLK_EN
0xFFC SENSITIVE_DATE
  [27:0] SENSITIVE_DATE
